# ISP6P5_GLBCE register map
Vendor: Texas Instruments
Peripheral module from a debugger description file (folder TDA2Px).
Registers are 32-bit, access per field, reset 0x0 unless marked. A register's access mark holds for its fields unless they carry their own. Offsets are as the file gives them; lines under a group give offsets from that group; [hi:lo] are bit positions; {n}, {i} and the like mark numbered series; 'fields as' and 'values as' point back to an identical list; <NAME> marks a mode.

## ISP6P5_GLBCE (part 1 of 2)
0x1FC GLBCE_FWD_PERCEPT_LUT_12 reset 0x6B1E
  [15:0] VAL rw — Forward Perceptual LUT enable
0x200 GLBCE_FWD_PERCEPT_LUT_13 reset 0x6FF9
  [15:0] VAL rw — Forward Perceptual LUT enable
0x204 GLBCE_FWD_PERCEPT_LUT_14 reset 0x74A1
  [15:0] VAL rw — Forward Perceptual LUT enable
0x208 GLBCE_FWD_PERCEPT_LUT_15 reset 0x791B
  [15:0] VAL rw — Forward Perceptual LUT enable
0x20C GLBCE_FWD_PERCEPT_LUT_16 reset 0x7D6C
  [15:0] VAL rw — Forward Perceptual LUT enable
0x210 GLBCE_FWD_PERCEPT_LUT_17 reset 0x8198
  [15:0] VAL rw — Forward Perceptual LUT enable
0x214 GLBCE_FWD_PERCEPT_LUT_18 reset 0x85A1
  [15:0] VAL rw — Forward Perceptual LUT enable
0x218 GLBCE_FWD_PERCEPT_LUT_19 reset 0x898B
  [15:0] VAL rw — Forward Perceptual LUT enable
0x21C GLBCE_FWD_PERCEPT_LUT_20 reset 0x8D59
  [15:0] VAL rw — Forward Perceptual LUT enable
0x220 GLBCE_FWD_PERCEPT_LUT_21 reset 0x910C
  [15:0] VAL rw — Forward Perceptual LUT enable
0x224 GLBCE_FWD_PERCEPT_LUT_22 reset 0x94A7
  [15:0] VAL rw — Forward Perceptual LUT enable
0x228 GLBCE_FWD_PERCEPT_LUT_23 reset 0x982B
  [15:0] VAL rw — Forward Perceptual LUT enable
0x22C GLBCE_FWD_PERCEPT_LUT_24 reset 0x9B9A
  [15:0] VAL rw — Forward Perceptual LUT enable
0x230 GLBCE_FWD_PERCEPT_LUT_25 reset 0x9EF5
  [15:0] VAL rw — Forward Perceptual LUT enable
0x234 GLBCE_FWD_PERCEPT_LUT_26 reset 0xA23D
  [15:0] VAL rw — Forward Perceptual LUT enable
0x238 GLBCE_FWD_PERCEPT_LUT_27 reset 0xA573
  [15:0] VAL rw — Forward Perceptual LUT enable
0x23C GLBCE_FWD_PERCEPT_LUT_28 reset 0xA899
  [15:0] VAL rw — Forward Perceptual LUT enable
0x240 GLBCE_FWD_PERCEPT_LUT_29 reset 0xABAF
  [15:0] VAL rw — Forward Perceptual LUT enable
0x244 GLBCE_FWD_PERCEPT_LUT_30 reset 0xAEB7
  [15:0] VAL rw — Forward Perceptual LUT enable
0x248 GLBCE_FWD_PERCEPT_LUT_31 reset 0xB1B0
  [15:0] VAL rw — Forward Perceptual LUT enable
0x24C GLBCE_FWD_PERCEPT_LUT_32 reset 0xB49C
  [15:0] VAL rw — Forward Perceptual LUT enable
0x250 GLBCE_FWD_PERCEPT_LUT_33 reset 0xB77B
  [15:0] VAL rw — Forward Perceptual LUT enable
0x254 GLBCE_FWD_PERCEPT_LUT_34 reset 0xBA4E
  [15:0] VAL rw — Forward Perceptual LUT enable
0x258 GLBCE_FWD_PERCEPT_LUT_35 reset 0xBD15
  [15:0] VAL rw — Forward Perceptual LUT enable
0x25C GLBCE_FWD_PERCEPT_LUT_36 reset 0xBFD2
  [15:0] VAL rw — Forward Perceptual LUT enable
0x260 GLBCE_FWD_PERCEPT_LUT_37 reset 0xC283
  [15:0] VAL rw — Forward Perceptual LUT enable
0x264 GLBCE_FWD_PERCEPT_LUT_38 reset 0xC52B
  [15:0] VAL rw — Forward Perceptual LUT enable
0x268 GLBCE_FWD_PERCEPT_LUT_39 reset 0xC7C9
  [15:0] VAL rw — Forward Perceptual LUT enable
0x26C GLBCE_FWD_PERCEPT_LUT_40 reset 0xCA5D
  [15:0] VAL rw — Forward Perceptual LUT enable
0x270 GLBCE_FWD_PERCEPT_LUT_41 reset 0xCCE8
  [15:0] VAL rw — Forward Perceptual LUT enable
0x274 GLBCE_FWD_PERCEPT_LUT_42 reset 0xCF6B
  [15:0] VAL rw — Forward Perceptual LUT enable
0x278 GLBCE_FWD_PERCEPT_LUT_43 reset 0xD1E5
  [15:0] VAL rw — Forward Perceptual LUT enable
0x27C GLBCE_FWD_PERCEPT_LUT_44 reset 0xD458
  [15:0] VAL rw — Forward Perceptual LUT enable
0x280 GLBCE_FWD_PERCEPT_LUT_45 reset 0xD6C2
  [15:0] VAL rw — Forward Perceptual LUT enable
0x284 GLBCE_FWD_PERCEPT_LUT_46 reset 0xD925
  [15:0] VAL rw — Forward Perceptual LUT enable
0x288 GLBCE_FWD_PERCEPT_LUT_47 reset 0xDB81
  [15:0] VAL rw — Forward Perceptual LUT enable
0x28C GLBCE_FWD_PERCEPT_LUT_48 reset 0xDDD5
  [15:0] VAL rw — Forward Perceptual LUT enable
0x290 GLBCE_FWD_PERCEPT_LUT_49 reset 0xE023
  [15:0] VAL rw — Forward Perceptual LUT enable
0x294 GLBCE_FWD_PERCEPT_LUT_50 reset 0xE26B
  [15:0] VAL rw — Forward Perceptual LUT enable
0x298 GLBCE_FWD_PERCEPT_LUT_51 reset 0xE4AB
  [15:0] VAL rw — Forward Perceptual LUT enable
0x29C GLBCE_FWD_PERCEPT_LUT_52 reset 0xE6E6
  [15:0] VAL rw — Forward Perceptual LUT enable
0x2A0 GLBCE_FWD_PERCEPT_LUT_53 reset 0xE91B
  [15:0] VAL rw — Forward Perceptual LUT enable
0x2A4 GLBCE_FWD_PERCEPT_LUT_54 reset 0xEB4A
  [15:0] VAL rw — Forward Perceptual LUT enable
0x2A8 GLBCE_FWD_PERCEPT_LUT_55 reset 0xED73
  [15:0] VAL rw — Forward Perceptual LUT enable
0x2AC GLBCE_FWD_PERCEPT_LUT_56 reset 0xEF97
  [15:0] VAL rw — Forward Perceptual LUT enable
0x2B0 GLBCE_FWD_PERCEPT_LUT_57 reset 0xF1B5
  [15:0] VAL rw — Forward Perceptual LUT enable
0x2B4 GLBCE_FWD_PERCEPT_LUT_58 reset 0xF3CE
  [15:0] VAL rw — Forward Perceptual LUT enable
0x2B8 GLBCE_FWD_PERCEPT_LUT_59 reset 0xF5E2
  [15:0] VAL rw — Forward Perceptual LUT enable
0x2BC GLBCE_FWD_PERCEPT_LUT_60 reset 0xF7F1
  [15:0] VAL rw — Forward Perceptual LUT enable
0x2C0 GLBCE_FWD_PERCEPT_LUT_61 reset 0xF9FC
  [15:0] VAL rw — Forward Perceptual LUT enable
0x2C4 GLBCE_FWD_PERCEPT_LUT_62 reset 0xFC01
  [15:0] VAL rw — Forward Perceptual LUT enable
0x2C8 GLBCE_FWD_PERCEPT_LUT_63 reset 0xFE02
  [15:0] VAL rw — Forward Perceptual LUT enable
0x2CC GLBCE_FWD_PERCEPT_LUT_64 reset 0xFFFF
  [15:0] VAL rw — Forward Perceptual LUT enable
0x2D0 GLBCE_WDR_GAMMA_EN
  [0] EN rw — Frontend WDR LUT enable
    0=DISABLE; 1=ENABLE
0x2D4 GLBCE_WDR_GAMMA_LUT_00 — Frontend WDR LUT
  [15:0] VAL rw
0x2D8 GLBCE_WDR_GAMMA_LUT_01 reset 0x100 — Frontend WDR LUT
  [15:0] VAL rw
0x2DC GLBCE_WDR_GAMMA_LUT_02 reset 0x200 — Frontend WDR LUT
  [15:0] VAL rw
0x2E0 GLBCE_WDR_GAMMA_LUT_03 reset 0x300 — Frontend WDR LUT
  [15:0] VAL rw
0x2E4 GLBCE_WDR_GAMMA_LUT_04 reset 0x400 — Frontend WDR LUT
  [15:0] VAL rw
0x2E8 GLBCE_WDR_GAMMA_LUT_05 reset 0x500 — Frontend WDR LUT
  [15:0] VAL rw
0x2EC GLBCE_WDR_GAMMA_LUT_06 reset 0x600 — Frontend WDR LUT
  [15:0] VAL rw
0x2F0 GLBCE_WDR_GAMMA_LUT_07 reset 0x700 — Frontend WDR LUT
  [15:0] VAL rw
0x2F4 GLBCE_WDR_GAMMA_LUT_08 reset 0x800 — Frontend WDR LUT
  [15:0] VAL rw
0x2F8 GLBCE_WDR_GAMMA_LUT_09 reset 0x900 — Frontend WDR LUT
  [15:0] VAL rw
0x2FC GLBCE_WDR_GAMMA_LUT_10 reset 0xA00 — Frontend WDR LUT
  [15:0] VAL rw
0x300 GLBCE_WDR_GAMMA_LUT_11 reset 0xB00 — Frontend WDR LUT
  [15:0] VAL rw
0x304 GLBCE_WDR_GAMMA_LUT_12 reset 0xC00 — Frontend WDR LUT
  [15:0] VAL rw
0x308 GLBCE_WDR_GAMMA_LUT_13 reset 0xD00 — Frontend WDR LUT
  [15:0] VAL rw
0x30C GLBCE_WDR_GAMMA_LUT_14 reset 0xE00 — Frontend WDR LUT
  [15:0] VAL rw
0x310 GLBCE_WDR_GAMMA_LUT_15 reset 0xF00 — Frontend WDR LUT
  [15:0] VAL rw
0x314 GLBCE_WDR_GAMMA_LUT_16 reset 0x1000 — Frontend WDR LUT
  [15:0] VAL rw
0x318 GLBCE_WDR_GAMMA_LUT_17 reset 0x1100 — Frontend WDR LUT
  [15:0] VAL rw
0x31C GLBCE_WDR_GAMMA_LUT_18 reset 0x1200 — Frontend WDR LUT
  [15:0] VAL rw
0x320 GLBCE_WDR_GAMMA_LUT_19 reset 0x1300 — Frontend WDR LUT
  [15:0] VAL rw
0x324 GLBCE_WDR_GAMMA_LUT_20 reset 0x1400 — Frontend WDR LUT
  [15:0] VAL rw
0x328 GLBCE_WDR_GAMMA_LUT_21 reset 0x1500 — Frontend WDR LUT
  [15:0] VAL rw
0x32C GLBCE_WDR_GAMMA_LUT_22 reset 0x1600 — Frontend WDR LUT
  [15:0] VAL rw
0x330 GLBCE_WDR_GAMMA_LUT_23 reset 0x1700 — Frontend WDR LUT
  [15:0] VAL rw
0x334 GLBCE_WDR_GAMMA_LUT_24 reset 0x1800 — Frontend WDR LUT
  [15:0] VAL rw
0x338 GLBCE_WDR_GAMMA_LUT_25 reset 0x1900 — Frontend WDR LUT
  [15:0] VAL rw
0x33C GLBCE_WDR_GAMMA_LUT_26 reset 0x1A00 — Frontend WDR LUT
  [15:0] VAL rw
0x340 GLBCE_WDR_GAMMA_LUT_27 reset 0x1B00 — Frontend WDR LUT
  [15:0] VAL rw
0x344 GLBCE_WDR_GAMMA_LUT_28 reset 0x1C00 — Frontend WDR LUT
  [15:0] VAL rw
0x348 GLBCE_WDR_GAMMA_LUT_29 reset 0x1D00 — Frontend WDR LUT
  [15:0] VAL rw
0x34C GLBCE_WDR_GAMMA_LUT_30 reset 0x1E00 — Frontend WDR LUT
  [15:0] VAL rw
0x350 GLBCE_WDR_GAMMA_LUT_31 reset 0x1F00 — Frontend WDR LUT
  [15:0] VAL rw
0x354 GLBCE_WDR_GAMMA_LUT_32 reset 0x2000 — Frontend WDR LUT
  [15:0] VAL rw
0x358 GLBCE_WDR_GAMMA_LUT_33 reset 0x2100 — Frontend WDR LUT
  [15:0] VAL rw
0x35C GLBCE_WDR_GAMMA_LUT_34 reset 0x2200 — Frontend WDR LUT
  [15:0] VAL rw
0x360 GLBCE_WDR_GAMMA_LUT_35 reset 0x2300 — Frontend WDR LUT
  [15:0] VAL rw
0x364 GLBCE_WDR_GAMMA_LUT_36 reset 0x2400 — Frontend WDR LUT
  [15:0] VAL rw
0x368 GLBCE_WDR_GAMMA_LUT_37 reset 0x2500 — Frontend WDR LUT
  [15:0] VAL rw
0x36C GLBCE_WDR_GAMMA_LUT_38 reset 0x2600 — Frontend WDR LUT
  [15:0] VAL rw
0x370 GLBCE_WDR_GAMMA_LUT_39 reset 0x2700 — Frontend WDR LUT
  [15:0] VAL rw
0x374 GLBCE_WDR_GAMMA_LUT_40 reset 0x2800 — Frontend WDR LUT
  [15:0] VAL rw
0x378 GLBCE_WDR_GAMMA_LUT_41 reset 0x2900 — Frontend WDR LUT
  [15:0] VAL rw
0x37C GLBCE_WDR_GAMMA_LUT_42 reset 0x2A00 — Frontend WDR LUT
  [15:0] VAL rw
0x380 GLBCE_WDR_GAMMA_LUT_43 reset 0x2B00 — Frontend WDR LUT
  [15:0] VAL rw
0x384 GLBCE_WDR_GAMMA_LUT_44 reset 0x2C00 — Frontend WDR LUT
  [15:0] VAL rw
0x388 GLBCE_WDR_GAMMA_LUT_45 reset 0x2D00 — Frontend WDR LUT
  [15:0] VAL rw
0x38C GLBCE_WDR_GAMMA_LUT_46 reset 0x2E00 — Frontend WDR LUT
  [15:0] VAL rw
0x390 GLBCE_WDR_GAMMA_LUT_47 reset 0x2F00 — Frontend WDR LUT
  [15:0] VAL rw
0x394 GLBCE_WDR_GAMMA_LUT_48 reset 0x3000 — Frontend WDR LUT
  [15:0] VAL rw
0x398 GLBCE_WDR_GAMMA_LUT_49 reset 0x3100 — Frontend WDR LUT
  [15:0] VAL rw
0x39C GLBCE_WDR_GAMMA_LUT_50 reset 0x3200 — Frontend WDR LUT
  [15:0] VAL rw
0x3A0 GLBCE_WDR_GAMMA_LUT_51 reset 0x3300 — Frontend WDR LUT
  [15:0] VAL rw
0x3A4 GLBCE_WDR_GAMMA_LUT_52 reset 0x3400 — Frontend WDR LUT
  [15:0] VAL rw
0x3A8 GLBCE_WDR_GAMMA_LUT_53 reset 0x3500 — Frontend WDR LUT
  [15:0] VAL rw
0x3AC GLBCE_WDR_GAMMA_LUT_54 reset 0x3600 — Frontend WDR LUT
  [15:0] VAL rw
0x3B0 GLBCE_WDR_GAMMA_LUT_55 reset 0x3700 — Frontend WDR LUT
  [15:0] VAL rw
0x3B4 GLBCE_WDR_GAMMA_LUT_56 reset 0x3800 — Frontend WDR LUT
  [15:0] VAL rw
0x3B8 GLBCE_WDR_GAMMA_LUT_57 reset 0x3900 — Frontend WDR LUT
  [15:0] VAL rw
0x3BC GLBCE_WDR_GAMMA_LUT_58 reset 0x3A00 — Frontend WDR LUT
  [15:0] VAL rw
0x3C0 GLBCE_WDR_GAMMA_LUT_59 reset 0x3B00 — Frontend WDR LUT
  [15:0] VAL rw
0x3C4 GLBCE_WDR_GAMMA_LUT_60 reset 0x3C00 — Frontend WDR LUT
  [15:0] VAL rw
0x3C8 GLBCE_WDR_GAMMA_LUT_61 reset 0x3D00 — Frontend WDR LUT
  [15:0] VAL rw
0x3CC GLBCE_WDR_GAMMA_LUT_62 reset 0x3E00 — Frontend WDR LUT
  [15:0] VAL rw
0x3D0 GLBCE_WDR_GAMMA_LUT_63 reset 0x3F00 — Frontend WDR LUT
  [15:0] VAL rw
0x3D4 GLBCE_WDR_GAMMA_LUT_64 reset 0x4000 — Frontend WDR LUT
  [15:0] VAL rw
0x3D8 GLBCE_WDR_GAMMA_LUT_65 reset 0x4100 — Frontend WDR LUT
  [15:0] VAL rw
0x3DC GLBCE_WDR_GAMMA_LUT_66 reset 0x4200 — Frontend WDR LUT
  [15:0] VAL rw
0x3E0 GLBCE_WDR_GAMMA_LUT_67 reset 0x4300 — Frontend WDR LUT
  [15:0] VAL rw
0x3E4 GLBCE_WDR_GAMMA_LUT_68 reset 0x4400 — Frontend WDR LUT
  [15:0] VAL rw
0x3E8 GLBCE_WDR_GAMMA_LUT_69 reset 0x4500 — Frontend WDR LUT
  [15:0] VAL rw
0x3EC GLBCE_WDR_GAMMA_LUT_70 reset 0x4600 — Frontend WDR LUT
  [15:0] VAL rw
0x3F0 GLBCE_WDR_GAMMA_LUT_71 reset 0x4700 — Frontend WDR LUT
  [15:0] VAL rw
0x3F4 GLBCE_WDR_GAMMA_LUT_72 reset 0x4800 — Frontend WDR LUT
  [15:0] VAL rw
0x3F8 GLBCE_WDR_GAMMA_LUT_73 reset 0x4900 — Frontend WDR LUT
  [15:0] VAL rw
0x3FC GLBCE_WDR_GAMMA_LUT_74 reset 0x4A00 — Frontend WDR LUT
  [15:0] VAL rw
0x400 GLBCE_WDR_GAMMA_LUT_75 reset 0x4B00 — Frontend WDR LUT
  [15:0] VAL rw
0x404 GLBCE_WDR_GAMMA_LUT_76 reset 0x4C00 — Frontend WDR LUT
  [15:0] VAL rw
0x408 GLBCE_WDR_GAMMA_LUT_77 reset 0x4D00 — Frontend WDR LUT
  [15:0] VAL rw
0x40C GLBCE_WDR_GAMMA_LUT_78 reset 0x4E00 — Frontend WDR LUT
  [15:0] VAL rw
0x410 GLBCE_WDR_GAMMA_LUT_79 reset 0x4F00 — Frontend WDR LUT
  [15:0] VAL rw
0x414 GLBCE_WDR_GAMMA_LUT_80 reset 0x5000 — Frontend WDR LUT
  [15:0] VAL rw
0x418 GLBCE_WDR_GAMMA_LUT_81 reset 0x5100 — Frontend WDR LUT
  [15:0] VAL rw
0x41C GLBCE_WDR_GAMMA_LUT_82 reset 0x5200 — Frontend WDR LUT
  [15:0] VAL rw
0x420 GLBCE_WDR_GAMMA_LUT_83 reset 0x5300 — Frontend WDR LUT
  [15:0] VAL rw
0x424 GLBCE_WDR_GAMMA_LUT_84 reset 0x5400 — Frontend WDR LUT
  [15:0] VAL rw
0x428 GLBCE_WDR_GAMMA_LUT_85 reset 0x5500 — Frontend WDR LUT
  [15:0] VAL rw
0x42C GLBCE_WDR_GAMMA_LUT_86 reset 0x5600 — Frontend WDR LUT
  [15:0] VAL rw
0x430 GLBCE_WDR_GAMMA_LUT_87 reset 0x5700 — Frontend WDR LUT
  [15:0] VAL rw
0x434 GLBCE_WDR_GAMMA_LUT_88 reset 0x5800 — Frontend WDR LUT
  [15:0] VAL rw
0x438 GLBCE_WDR_GAMMA_LUT_89 reset 0x5900 — Frontend WDR LUT
  [15:0] VAL rw
0x43C GLBCE_WDR_GAMMA_LUT_90 reset 0x5A00 — Frontend WDR LUT
  [15:0] VAL rw
0x440 GLBCE_WDR_GAMMA_LUT_91 reset 0x5B00 — Frontend WDR LUT
  [15:0] VAL rw
0x444 GLBCE_WDR_GAMMA_LUT_92 reset 0x5C00 — Frontend WDR LUT
  [15:0] VAL rw
0x448 GLBCE_WDR_GAMMA_LUT_93 reset 0x5D00 — Frontend WDR LUT
  [15:0] VAL rw
0x44C GLBCE_WDR_GAMMA_LUT_94 reset 0x5E00 — Frontend WDR LUT
  [15:0] VAL rw
0x450 GLBCE_WDR_GAMMA_LUT_95 reset 0x5F00 — Frontend WDR LUT
  [15:0] VAL rw
0x454 GLBCE_WDR_GAMMA_LUT_96 reset 0x6000 — Frontend WDR LUT
  [15:0] VAL rw
0x458 GLBCE_WDR_GAMMA_LUT_97 reset 0x6100 — Frontend WDR LUT
  [15:0] VAL rw
0x45C GLBCE_WDR_GAMMA_LUT_98 reset 0x6200 — Frontend WDR LUT
  [15:0] VAL rw
0x460 GLBCE_WDR_GAMMA_LUT_99 reset 0x6300 — Frontend WDR LUT
  [15:0] VAL rw
0x464 GLBCE_WDR_GAMMA_LUT_100 reset 0x6400 — Frontend WDR LUT
  [15:0] VAL rw
0x468 GLBCE_WDR_GAMMA_LUT_101 reset 0x6500 — Frontend WDR LUT
  [15:0] VAL rw
0x46C GLBCE_WDR_GAMMA_LUT_102 reset 0x6600 — Frontend WDR LUT
  [15:0] VAL rw
0x470 GLBCE_WDR_GAMMA_LUT_103 reset 0x6700 — Frontend WDR LUT
  [15:0] VAL rw
0x474 GLBCE_WDR_GAMMA_LUT_104 reset 0x6800 — Frontend WDR LUT
  [15:0] VAL rw
0x478 GLBCE_WDR_GAMMA_LUT_105 reset 0x6900 — Frontend WDR LUT
  [15:0] VAL rw
0x47C GLBCE_WDR_GAMMA_LUT_106 reset 0x6A00 — Frontend WDR LUT
  [15:0] VAL rw
0x480 GLBCE_WDR_GAMMA_LUT_107 reset 0x6B00 — Frontend WDR LUT
  [15:0] VAL rw
0x484 GLBCE_WDR_GAMMA_LUT_108 reset 0x6C00 — Frontend WDR LUT
  [15:0] VAL rw
0x488 GLBCE_WDR_GAMMA_LUT_109 reset 0x6D00 — Frontend WDR LUT
  [15:0] VAL rw
0x48C GLBCE_WDR_GAMMA_LUT_110 reset 0x6E00 — Frontend WDR LUT
  [15:0] VAL rw
0x490 GLBCE_WDR_GAMMA_LUT_111 reset 0x6F00 — Frontend WDR LUT
  [15:0] VAL rw
0x494 GLBCE_WDR_GAMMA_LUT_112 reset 0x7000 — Frontend WDR LUT
  [15:0] VAL rw
0x498 GLBCE_WDR_GAMMA_LUT_113 reset 0x7100 — Frontend WDR LUT
  [15:0] VAL rw
0x49C GLBCE_WDR_GAMMA_LUT_114 reset 0x7200 — Frontend WDR LUT
  [15:0] VAL rw
0x4A0 GLBCE_WDR_GAMMA_LUT_115 reset 0x7300 — Frontend WDR LUT
  [15:0] VAL rw
0x4A4 GLBCE_WDR_GAMMA_LUT_116 reset 0x7400 — Frontend WDR LUT
  [15:0] VAL rw
0x4A8 GLBCE_WDR_GAMMA_LUT_117 reset 0x7500 — Frontend WDR LUT
  [15:0] VAL rw
0x4AC GLBCE_WDR_GAMMA_LUT_118 reset 0x7600 — Frontend WDR LUT
  [15:0] VAL rw
0x4B0 GLBCE_WDR_GAMMA_LUT_119 reset 0x7700 — Frontend WDR LUT
  [15:0] VAL rw
0x4B4 GLBCE_WDR_GAMMA_LUT_120 reset 0x7800 — Frontend WDR LUT
  [15:0] VAL rw
0x4B8 GLBCE_WDR_GAMMA_LUT_121 reset 0x7900 — Frontend WDR LUT
  [15:0] VAL rw
0x4BC GLBCE_WDR_GAMMA_LUT_122 reset 0x7A00 — Frontend WDR LUT
  [15:0] VAL rw
0x4C0 GLBCE_WDR_GAMMA_LUT_123 reset 0x7B00 — Frontend WDR LUT
  [15:0] VAL rw
0x4C4 GLBCE_WDR_GAMMA_LUT_124 reset 0x7C00 — Frontend WDR LUT
  [15:0] VAL rw
0x4C8 GLBCE_WDR_GAMMA_LUT_125 reset 0x7D00 — Frontend WDR LUT
  [15:0] VAL rw
0x4CC GLBCE_WDR_GAMMA_LUT_126 reset 0x7E00 — Frontend WDR LUT
  [15:0] VAL rw
0x4D0 GLBCE_WDR_GAMMA_LUT_127 reset 0x7F00 — Frontend WDR LUT
  [15:0] VAL rw
0x4D4 GLBCE_WDR_GAMMA_LUT_128 reset 0x8000 — Frontend WDR LUT
  [15:0] VAL rw
0x4D8 GLBCE_WDR_GAMMA_LUT_129 reset 0x8100 — Frontend WDR LUT
  [15:0] VAL rw
0x4DC GLBCE_WDR_GAMMA_LUT_130 reset 0x8200 — Frontend WDR LUT
  [15:0] VAL rw
0x4E0 GLBCE_WDR_GAMMA_LUT_131 reset 0x8300 — Frontend WDR LUT
  [15:0] VAL rw
0x4E4 GLBCE_WDR_GAMMA_LUT_132 reset 0x8400 — Frontend WDR LUT
  [15:0] VAL rw
0x4E8 GLBCE_WDR_GAMMA_LUT_133 reset 0x8500 — Frontend WDR LUT
  [15:0] VAL rw
0x4EC GLBCE_WDR_GAMMA_LUT_134 reset 0x8600 — Frontend WDR LUT
  [15:0] VAL rw
0x4F0 GLBCE_WDR_GAMMA_LUT_135 reset 0x8700 — Frontend WDR LUT
  [15:0] VAL rw
0x4F4 GLBCE_WDR_GAMMA_LUT_136 reset 0x8800 — Frontend WDR LUT
  [15:0] VAL rw
0x4F8 GLBCE_WDR_GAMMA_LUT_137 reset 0x8900 — Frontend WDR LUT
  [15:0] VAL rw
0x4FC GLBCE_WDR_GAMMA_LUT_138 reset 0x8A00 — Frontend WDR LUT
  [15:0] VAL rw
0x500 GLBCE_WDR_GAMMA_LUT_139 reset 0x8B00 — Frontend WDR LUT
  [15:0] VAL rw
0x504 GLBCE_WDR_GAMMA_LUT_140 reset 0x8C00 — Frontend WDR LUT
  [15:0] VAL rw
0x508 GLBCE_WDR_GAMMA_LUT_141 reset 0x8D00 — Frontend WDR LUT
  [15:0] VAL rw
0x50C GLBCE_WDR_GAMMA_LUT_142 reset 0x8E00 — Frontend WDR LUT
  [15:0] VAL rw
0x510 GLBCE_WDR_GAMMA_LUT_143 reset 0x8F00 — Frontend WDR LUT
  [15:0] VAL rw
0x514 GLBCE_WDR_GAMMA_LUT_144 reset 0x9000 — Frontend WDR LUT
  [15:0] VAL rw
0x518 GLBCE_WDR_GAMMA_LUT_145 reset 0x9100 — Frontend WDR LUT
  [15:0] VAL rw
0x51C GLBCE_WDR_GAMMA_LUT_146 reset 0x9200 — Frontend WDR LUT
  [15:0] VAL rw
0x520 GLBCE_WDR_GAMMA_LUT_147 reset 0x9300 — Frontend WDR LUT
  [15:0] VAL rw
0x524 GLBCE_WDR_GAMMA_LUT_148 reset 0x9400 — Frontend WDR LUT
  [15:0] VAL rw
0x528 GLBCE_WDR_GAMMA_LUT_149 reset 0x9500 — Frontend WDR LUT
  [15:0] VAL rw
0x52C GLBCE_WDR_GAMMA_LUT_150 reset 0x9600 — Frontend WDR LUT
  [15:0] VAL rw
0x530 GLBCE_WDR_GAMMA_LUT_151 reset 0x9700 — Frontend WDR LUT
  [15:0] VAL rw
0x534 GLBCE_WDR_GAMMA_LUT_152 reset 0x9800 — Frontend WDR LUT
  [15:0] VAL rw
0x538 GLBCE_WDR_GAMMA_LUT_153 reset 0x9900 — Frontend WDR LUT
  [15:0] VAL rw
0x53C GLBCE_WDR_GAMMA_LUT_154 reset 0x9A00 — Frontend WDR LUT
  [15:0] VAL rw
0x540 GLBCE_WDR_GAMMA_LUT_155 reset 0x9B00 — Frontend WDR LUT
  [15:0] VAL rw
0x544 GLBCE_WDR_GAMMA_LUT_156 reset 0x9C00 — Frontend WDR LUT
  [15:0] VAL rw
0x548 GLBCE_WDR_GAMMA_LUT_157 reset 0x9D00 — Frontend WDR LUT
  [15:0] VAL rw
0x54C GLBCE_WDR_GAMMA_LUT_158 reset 0x9E00 — Frontend WDR LUT
  [15:0] VAL rw
0x550 GLBCE_WDR_GAMMA_LUT_159 reset 0x9F00 — Frontend WDR LUT
  [15:0] VAL rw
0x554 GLBCE_WDR_GAMMA_LUT_160 reset 0xA000 — Frontend WDR LUT
  [15:0] VAL rw
0x558 GLBCE_WDR_GAMMA_LUT_161 reset 0xA100 — Frontend WDR LUT
  [15:0] VAL rw
0x55C GLBCE_WDR_GAMMA_LUT_162 reset 0xA200 — Frontend WDR LUT
  [15:0] VAL rw
0x560 GLBCE_WDR_GAMMA_LUT_163 reset 0xA300 — Frontend WDR LUT
  [15:0] VAL rw
0x564 GLBCE_WDR_GAMMA_LUT_164 reset 0xA400 — Frontend WDR LUT
  [15:0] VAL rw
0x568 GLBCE_WDR_GAMMA_LUT_165 reset 0xA500 — Frontend WDR LUT
  [15:0] VAL rw
0x56C GLBCE_WDR_GAMMA_LUT_166 reset 0xA600 — Frontend WDR LUT
  [15:0] VAL rw
0x570 GLBCE_WDR_GAMMA_LUT_167 reset 0xA700 — Frontend WDR LUT
  [15:0] VAL rw
0x574 GLBCE_WDR_GAMMA_LUT_168 reset 0xA800 — Frontend WDR LUT
  [15:0] VAL rw
0x578 GLBCE_WDR_GAMMA_LUT_169 reset 0xA900 — Frontend WDR LUT
  [15:0] VAL rw
0x57C GLBCE_WDR_GAMMA_LUT_170 reset 0xAA00 — Frontend WDR LUT
  [15:0] VAL rw
0x580 GLBCE_WDR_GAMMA_LUT_171 reset 0xAB00 — Frontend WDR LUT
  [15:0] VAL rw
0x584 GLBCE_WDR_GAMMA_LUT_172 reset 0xAC00 — Frontend WDR LUT
  [15:0] VAL rw
0x588 GLBCE_WDR_GAMMA_LUT_173 reset 0xAD00 — Frontend WDR LUT
  [15:0] VAL rw
0x58C GLBCE_WDR_GAMMA_LUT_174 reset 0xAE00 — Frontend WDR LUT
  [15:0] VAL rw
0x590 GLBCE_WDR_GAMMA_LUT_175 reset 0xAF00 — Frontend WDR LUT
  [15:0] VAL rw
0x594 GLBCE_WDR_GAMMA_LUT_176 reset 0xB000 — Frontend WDR LUT
  [15:0] VAL rw
0x598 GLBCE_WDR_GAMMA_LUT_177 reset 0xB100 — Frontend WDR LUT
  [15:0] VAL rw
0x59C GLBCE_WDR_GAMMA_LUT_178 reset 0xB200 — Frontend WDR LUT
  [15:0] VAL rw
0x5A0 GLBCE_WDR_GAMMA_LUT_179 reset 0xB300 — Frontend WDR LUT
  [15:0] VAL rw
0x5A4 GLBCE_WDR_GAMMA_LUT_180 reset 0xB400 — Frontend WDR LUT
  [15:0] VAL rw
0x5A8 GLBCE_WDR_GAMMA_LUT_181 reset 0xB500 — Frontend WDR LUT
  [15:0] VAL rw
0x5AC GLBCE_WDR_GAMMA_LUT_182 reset 0xB600 — Frontend WDR LUT
  [15:0] VAL rw
0x5B0 GLBCE_WDR_GAMMA_LUT_183 reset 0xB700 — Frontend WDR LUT
  [15:0] VAL rw
0x5B4 GLBCE_WDR_GAMMA_LUT_184 reset 0xB800 — Frontend WDR LUT
  [15:0] VAL rw
0x5B8 GLBCE_WDR_GAMMA_LUT_185 reset 0xB900 — Frontend WDR LUT
  [15:0] VAL rw
0x5BC GLBCE_WDR_GAMMA_LUT_186 reset 0xBA00 — Frontend WDR LUT
  [15:0] VAL rw
0x5C0 GLBCE_WDR_GAMMA_LUT_187 reset 0xBB00 — Frontend WDR LUT
  [15:0] VAL rw
0x5C4 GLBCE_WDR_GAMMA_LUT_188 reset 0xBC00 — Frontend WDR LUT
  [15:0] VAL rw
0x5C8 GLBCE_WDR_GAMMA_LUT_189 reset 0xBD00 — Frontend WDR LUT
  [15:0] VAL rw
0x5CC GLBCE_WDR_GAMMA_LUT_190 reset 0xBE00 — Frontend WDR LUT
  [15:0] VAL rw
0x5D0 GLBCE_WDR_GAMMA_LUT_191 reset 0xBF00 — Frontend WDR LUT
  [15:0] VAL rw
0x5D4 GLBCE_WDR_GAMMA_LUT_192 reset 0xC000 — Frontend WDR LUT
  [15:0] VAL rw
0x5D8 GLBCE_WDR_GAMMA_LUT_193 reset 0xC100 — Frontend WDR LUT
  [15:0] VAL rw
0x5DC GLBCE_WDR_GAMMA_LUT_194 reset 0xC200 — Frontend WDR LUT
  [15:0] VAL rw
0x5E0 GLBCE_WDR_GAMMA_LUT_195 reset 0xC300 — Frontend WDR LUT
  [15:0] VAL rw
0x5E4 GLBCE_WDR_GAMMA_LUT_196 reset 0xC400 — Frontend WDR LUT
  [15:0] VAL rw
0x5E8 GLBCE_WDR_GAMMA_LUT_197 reset 0xC500 — Frontend WDR LUT
  [15:0] VAL rw
0x5EC GLBCE_WDR_GAMMA_LUT_198 reset 0xC600 — Frontend WDR LUT
  [15:0] VAL rw
0x5F0 GLBCE_WDR_GAMMA_LUT_199 reset 0xC700 — Frontend WDR LUT
  [15:0] VAL rw
0x5F4 GLBCE_WDR_GAMMA_LUT_200 reset 0xC800 — Frontend WDR LUT
  [15:0] VAL rw
0x5F8 GLBCE_WDR_GAMMA_LUT_201 reset 0xC900 — Frontend WDR LUT
  [15:0] VAL rw
0x5FC GLBCE_WDR_GAMMA_LUT_202 reset 0xCA00 — Frontend WDR LUT
  [15:0] VAL rw
0x600 GLBCE_WDR_GAMMA_LUT_203 reset 0xCB00 — Frontend WDR LUT
  [15:0] VAL rw
0x604 GLBCE_WDR_GAMMA_LUT_204 reset 0xCC00 — Frontend WDR LUT
  [15:0] VAL rw
0x608 GLBCE_WDR_GAMMA_LUT_205 reset 0xCD00 — Frontend WDR LUT
  [15:0] VAL rw
0x60C GLBCE_WDR_GAMMA_LUT_206 reset 0xCE00 — Frontend WDR LUT
  [15:0] VAL rw
0x610 GLBCE_WDR_GAMMA_LUT_207 reset 0xCF00 — Frontend WDR LUT
  [15:0] VAL rw
0x614 GLBCE_WDR_GAMMA_LUT_208 reset 0xD000 — Frontend WDR LUT
  [15:0] VAL rw
0x618 GLBCE_WDR_GAMMA_LUT_209 reset 0xD100 — Frontend WDR LUT
  [15:0] VAL rw
0x61C GLBCE_WDR_GAMMA_LUT_210 reset 0xD200 — Frontend WDR LUT
  [15:0] VAL rw
0x620 GLBCE_WDR_GAMMA_LUT_211 reset 0xD300 — Frontend WDR LUT
  [15:0] VAL rw
0x624 GLBCE_WDR_GAMMA_LUT_212 reset 0xD400 — Frontend WDR LUT
  [15:0] VAL rw
0x628 GLBCE_WDR_GAMMA_LUT_213 reset 0xD500 — Frontend WDR LUT
  [15:0] VAL rw
0x62C GLBCE_WDR_GAMMA_LUT_214 reset 0xD600 — Frontend WDR LUT
  [15:0] VAL rw
0x630 GLBCE_WDR_GAMMA_LUT_215 reset 0xD700 — Frontend WDR LUT
  [15:0] VAL rw
0x634 GLBCE_WDR_GAMMA_LUT_216 reset 0xD800 — Frontend WDR LUT
  [15:0] VAL rw
0x638 GLBCE_WDR_GAMMA_LUT_217 reset 0xD900 — Frontend WDR LUT
  [15:0] VAL rw
0x63C GLBCE_WDR_GAMMA_LUT_218 reset 0xDA00 — Frontend WDR LUT
  [15:0] VAL rw
0x640 GLBCE_WDR_GAMMA_LUT_219 reset 0xDB00 — Frontend WDR LUT
  [15:0] VAL rw
0x644 GLBCE_WDR_GAMMA_LUT_220 reset 0xDC00 — Frontend WDR LUT
  [15:0] VAL rw
0x648 GLBCE_WDR_GAMMA_LUT_221 reset 0xDD00 — Frontend WDR LUT
  [15:0] VAL rw
0x64C GLBCE_WDR_GAMMA_LUT_222 reset 0xDE00 — Frontend WDR LUT
  [15:0] VAL rw
0x650 GLBCE_WDR_GAMMA_LUT_223 reset 0xDF00 — Frontend WDR LUT
  [15:0] VAL rw
0x654 GLBCE_WDR_GAMMA_LUT_224 reset 0xE000 — Frontend WDR LUT
  [15:0] VAL rw
0x658 GLBCE_WDR_GAMMA_LUT_225 reset 0xE100 — Frontend WDR LUT
  [15:0] VAL rw
0x65C GLBCE_WDR_GAMMA_LUT_226 reset 0xE200 — Frontend WDR LUT
  [15:0] VAL rw
0x660 GLBCE_WDR_GAMMA_LUT_227 reset 0xE300 — Frontend WDR LUT
  [15:0] VAL rw
0x664 GLBCE_WDR_GAMMA_LUT_228 reset 0xE400 — Frontend WDR LUT
  [15:0] VAL rw
0x668 GLBCE_WDR_GAMMA_LUT_229 reset 0xE500 — Frontend WDR LUT
  [15:0] VAL rw
0x66C GLBCE_WDR_GAMMA_LUT_230 reset 0xE600 — Frontend WDR LUT
  [15:0] VAL rw
0x670 GLBCE_WDR_GAMMA_LUT_231 reset 0xE700 — Frontend WDR LUT
  [15:0] VAL rw
0x674 GLBCE_WDR_GAMMA_LUT_232 reset 0xE800 — Frontend WDR LUT
  [15:0] VAL rw
0x678 GLBCE_WDR_GAMMA_LUT_233 reset 0xE900 — Frontend WDR LUT
  [15:0] VAL rw
0x67C GLBCE_WDR_GAMMA_LUT_234 reset 0xEA00 — Frontend WDR LUT
  [15:0] VAL rw
0x680 GLBCE_WDR_GAMMA_LUT_235 reset 0xEB00 — Frontend WDR LUT
  [15:0] VAL rw
0x684 GLBCE_WDR_GAMMA_LUT_236 reset 0xEC00 — Frontend WDR LUT
  [15:0] VAL rw
0x688 GLBCE_WDR_GAMMA_LUT_237 reset 0xED00 — Frontend WDR LUT
  [15:0] VAL rw
0x68C GLBCE_WDR_GAMMA_LUT_238 reset 0xEE00 — Frontend WDR LUT
  [15:0] VAL rw
0x690 GLBCE_WDR_GAMMA_LUT_239 reset 0xEF00 — Frontend WDR LUT
  [15:0] VAL rw
0x694 GLBCE_WDR_GAMMA_LUT_240 reset 0xF000 — Frontend WDR LUT
  [15:0] VAL rw
0x698 GLBCE_WDR_GAMMA_LUT_241 reset 0xF100 — Frontend WDR LUT
  [15:0] VAL rw
0x69C GLBCE_WDR_GAMMA_LUT_242 reset 0xF200 — Frontend WDR LUT
  [15:0] VAL rw
0x6A0 GLBCE_WDR_GAMMA_LUT_243 reset 0xF300 — Frontend WDR LUT
  [15:0] VAL rw
0x6A4 GLBCE_WDR_GAMMA_LUT_244 reset 0xF400 — Frontend WDR LUT
  [15:0] VAL rw
0x6A8 GLBCE_WDR_GAMMA_LUT_245 reset 0xF500 — Frontend WDR LUT
  [15:0] VAL rw
0x6AC GLBCE_WDR_GAMMA_LUT_246 reset 0xF600 — Frontend WDR LUT
  [15:0] VAL rw
0x6B0 GLBCE_WDR_GAMMA_LUT_247 reset 0xF700 — Frontend WDR LUT
  [15:0] VAL rw
0x6B4 GLBCE_WDR_GAMMA_LUT_248 reset 0xF800 — Frontend WDR LUT
  [15:0] VAL rw
0x6B8 GLBCE_WDR_GAMMA_LUT_249 reset 0xF900 — Frontend WDR LUT
  [15:0] VAL rw
0x6BC GLBCE_WDR_GAMMA_LUT_250 reset 0xFA00 — Frontend WDR LUT
  [15:0] VAL rw
0x6C0 GLBCE_WDR_GAMMA_LUT_251 reset 0xFB00 — Frontend WDR LUT
  [15:0] VAL rw
0x6C4 GLBCE_WDR_GAMMA_LUT_252 reset 0xFC00 — Frontend WDR LUT
  [15:0] VAL rw
0x6C8 GLBCE_WDR_GAMMA_LUT_253 reset 0xFD00 — Frontend WDR LUT
  [15:0] VAL rw
0x6CC GLBCE_WDR_GAMMA_LUT_254 reset 0xFE00 — Frontend WDR LUT
  [15:0] VAL rw
0x6D0 GLBCE_WDR_GAMMA_LUT_255 reset 0xFF00 — Frontend WDR LUT
  [15:0] VAL rw
0x6D4 GLBCE_WDR_GAMMA_LUT_256 reset 0xFFFF — Frontend WDR LUT
  [15:0] VAL rw
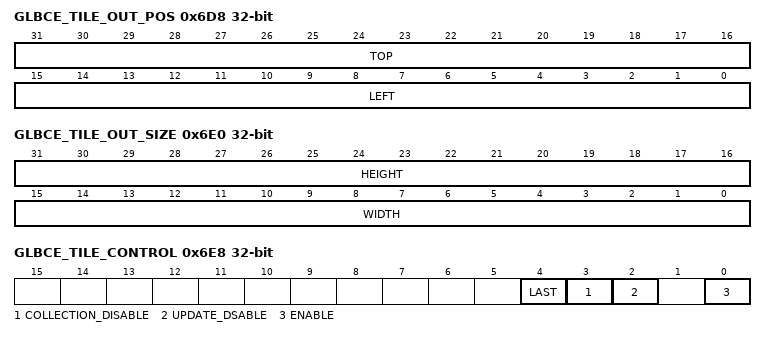
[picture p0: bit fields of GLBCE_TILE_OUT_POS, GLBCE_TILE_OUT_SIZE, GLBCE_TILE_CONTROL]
0x6D8 GLBCE_TILE_OUT_POS rw — Tile processing signals [TBD]
  [31:16] TOP, [15:0] LEFT
0x6E0 GLBCE_TILE_OUT_SIZE rw — Tile processing signals [TBD]
  [31:16] HEIGHT, [15:0] WIDTH
0x6E8 GLBCE_TILE_CONTROL
  [4] LAST rw — Last time
  [3] COLLECTION_DISABLE rw — Statistics collection disable
  [2] UPDATE_DSABLE rw — Statistics update disable
  [0] ENABLE rw — Tile processing Enable
0x6EC GLBCE_OUTPUT_FLAGS ro
  [15:0] TILE_STATUS
